AUTOSAR XML (schema 4-3-1)
standard types defined: Boolean, UInt8, SInt8, UInt16, SInt16, UInt32, SInt32, boolean, uint8, sint8, uint16, sint16, uint32, sint32
package /Components
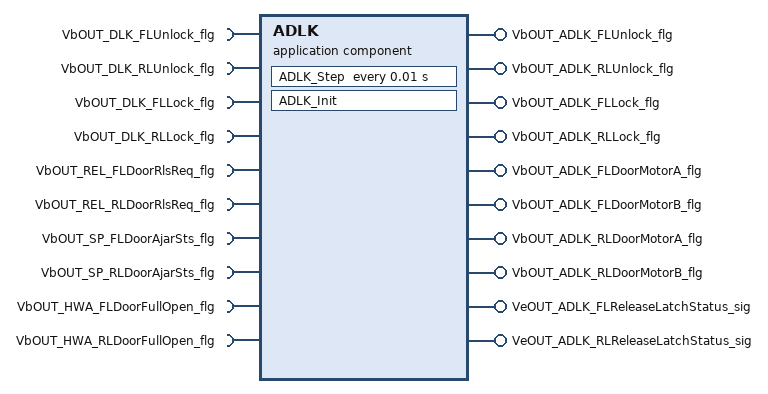
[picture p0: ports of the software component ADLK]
  application sw component type ADLK
    10 x require port:
      VbOUT_DLK_FLUnlock_flg: nonqueued-receiver-com-spec{data-element=VbOUT_DLK_FLUnlock_flg, init-value=FALSE}, required-interface=VbOUT_DLK_FLUnlock_flg
      VbOUT_DLK_RLUnlock_flg: nonqueued-receiver-com-spec{data-element=VbOUT_DLK_RLUnlock_flg, init-value=FALSE}, required-interface=VbOUT_DLK_RLUnlock_flg
      VbOUT_DLK_FLLock_flg: nonqueued-receiver-com-spec{data-element=VbOUT_DLK_FLLock_flg, init-value=FALSE}, required-interface=VbOUT_DLK_FLLock_flg
      VbOUT_DLK_RLLock_flg: nonqueued-receiver-com-spec{data-element=VbOUT_DLK_RLLock_flg, init-value=FALSE}, required-interface=VbOUT_DLK_RLLock_flg
      VbOUT_REL_FLDoorRlsReq_flg: nonqueued-receiver-com-spec{data-element=VbOUT_REL_FLDoorRlsReq_flg, init-value=FALSE}, required-interface=VbOUT_REL_FLDoorRlsReq_flg
      VbOUT_REL_RLDoorRlsReq_flg: nonqueued-receiver-com-spec{data-element=VbOUT_REL_RLDoorRlsReq_flg, init-value=FALSE}, required-interface=VbOUT_REL_RLDoorRlsReq_flg
      VbOUT_SP_FLDoorAjarSts_flg: nonqueued-receiver-com-spec{data-element=VbOUT_SP_FLDoorAjarSts_flg, init-value=FALSE}, required-interface=VbOUT_SP_FLDoorAjarSts_flg
      VbOUT_SP_RLDoorAjarSts_flg: nonqueued-receiver-com-spec{data-element=VbOUT_SP_RLDoorAjarSts_flg, init-value=FALSE}, required-interface=VbOUT_SP_RLDoorAjarSts_flg
      VbOUT_HWA_FLDoorFullOpen_flg: nonqueued-receiver-com-spec{data-element=VbOUT_HWA_FLDoorFullOpen_flg, init-value=FALSE}, required-interface=VbOUT_HWA_FLDoorFullOpen_flg
      VbOUT_HWA_RLDoorFullOpen_flg: nonqueued-receiver-com-spec{data-element=VbOUT_HWA_RLDoorFullOpen_flg, init-value=FALSE}, required-interface=VbOUT_HWA_RLDoorFullOpen_flg
    10 x provide port:
      VbOUT_ADLK_FLUnlock_flg: nonqueued-sender-com-spec{data-element=VbOUT_ADLK_FLUnlock_flg, init-value=FALSE}, provided-interface=VbOUT_ADLK_FLUnlock_flg
      VbOUT_ADLK_RLUnlock_flg: nonqueued-sender-com-spec{data-element=VbOUT_ADLK_RLUnlock_flg, init-value=FALSE}, provided-interface=VbOUT_ADLK_RLUnlock_flg
      VbOUT_ADLK_FLLock_flg: nonqueued-sender-com-spec{data-element=VbOUT_ADLK_FLLock_flg, init-value=FALSE}, provided-interface=VbOUT_ADLK_FLLock_flg
      VbOUT_ADLK_RLLock_flg: nonqueued-sender-com-spec{data-element=VbOUT_ADLK_RLLock_flg, init-value=FALSE}, provided-interface=VbOUT_ADLK_RLLock_flg
      VbOUT_ADLK_FLDoorMotorA_flg: nonqueued-sender-com-spec{data-element=VbOUT_ADLK_FLDoorMotorA_flg, init-value=FALSE}, provided-interface=VbOUT_ADLK_FLDoorMotorA_flg
      VbOUT_ADLK_FLDoorMotorB_flg: nonqueued-sender-com-spec{data-element=VbOUT_ADLK_FLDoorMotorB_flg, init-value=FALSE}, provided-interface=VbOUT_ADLK_FLDoorMotorB_flg
      VbOUT_ADLK_RLDoorMotorA_flg: nonqueued-sender-com-spec{data-element=VbOUT_ADLK_RLDoorMotorA_flg, init-value=FALSE}, provided-interface=VbOUT_ADLK_RLDoorMotorA_flg
      VbOUT_ADLK_RLDoorMotorB_flg: nonqueued-sender-com-spec{data-element=VbOUT_ADLK_RLDoorMotorB_flg, init-value=FALSE}, provided-interface=VbOUT_ADLK_RLDoorMotorB_flg
      VeOUT_ADLK_FLReleaseLatchStatus_sig: nonqueued-sender-com-spec{data-element=VeOUT_ADLK_FLReleaseLatchStatus_sig, init-value=0}, provided-interface=VeOUT_ADLK_FLReleaseLatchStatus_sig
      VeOUT_ADLK_RLReleaseLatchStatus_sig: nonqueued-sender-com-spec{data-element=VeOUT_ADLK_RLReleaseLatchStatus_sig, init-value=0}, provided-interface=VeOUT_ADLK_RLReleaseLatchStatus_sig
    behavior ADLK: data-type-mapping=DataTypeMappingsSet, handle-termination-and-restart=NO-SUPPORT
      init event ADLK_InitEvent: start-on-event=ADLK_Init
      timing event Event_Runnable_Step: start-on-event=ADLK_Step, period=0.01
      runnable ADLK_Init
        data-send-points:
          6 x access:
            OUT_VbOUT_ADLK_FLUnlock_flg_VbOUT_ADLK_FLUnlock_flg: accessed-variable=VbOUT_ADLK_FLUnlock_flg.VbOUT_ADLK_FLUnlock_flg
            OUT_VbOUT_ADLK_RLUnlock_flg_VbOUT_ADLK_RLUnlock_flg: accessed-variable=VbOUT_ADLK_RLUnlock_flg.VbOUT_ADLK_RLUnlock_flg
            OUT_VbOUT_ADLK_FLLock_flg_VbOUT_ADLK_FLLock_flg: accessed-variable=VbOUT_ADLK_FLLock_flg.VbOUT_ADLK_FLLock_flg
            OUT_VbOUT_ADLK_RLLock_flg_VbOUT_ADLK_RLLock_flg: accessed-variable=VbOUT_ADLK_RLLock_flg.VbOUT_ADLK_RLLock_flg
            OUT_VeOUT_ADLK_FLReleaseLatchStatus_sig_VeOUT_ADLK_FLReleaseLatchStatus_sig: accessed-variable=VeOUT_ADLK_FLReleaseLatchStatus_sig.VeOUT_ADLK_FLReleaseLatchStatus_sig
            OUT_VeOUT_ADLK_RLReleaseLatchStatus_sig_VeOUT_ADLK_RLReleaseLatchStatus_sig: accessed-variable=VeOUT_ADLK_RLReleaseLatchStatus_sig.VeOUT_ADLK_RLReleaseLatchStatus_sig
      runnable ADLK_Step
        data-receive-point-by-arguments:
          10 x access:
            IN_VbOUT_DLK_FLLock_flg_VbOUT_DLK_FLLock_flg: accessed-variable=VbOUT_DLK_FLLock_flg.VbOUT_DLK_FLLock_flg
            IN_VbOUT_DLK_FLUnlock_flg_VbOUT_DLK_FLUnlock_flg: accessed-variable=VbOUT_DLK_FLUnlock_flg.VbOUT_DLK_FLUnlock_flg
            IN_VbOUT_DLK_RLLock_flg_VbOUT_DLK_RLLock_flg: accessed-variable=VbOUT_DLK_RLLock_flg.VbOUT_DLK_RLLock_flg
            IN_VbOUT_DLK_RLUnlock_flg_VbOUT_DLK_RLUnlock_flg: accessed-variable=VbOUT_DLK_RLUnlock_flg.VbOUT_DLK_RLUnlock_flg
            IN_VbOUT_HWA_FLDoorFullOpen_flg_VbOUT_HWA_FLDoorFullOpen_flg: accessed-variable=VbOUT_HWA_FLDoorFullOpen_flg.VbOUT_HWA_FLDoorFullOpen_flg
            IN_VbOUT_HWA_RLDoorFullOpen_flg_VbOUT_HWA_RLDoorFullOpen_flg: accessed-variable=VbOUT_HWA_RLDoorFullOpen_flg.VbOUT_HWA_RLDoorFullOpen_flg
            IN_VbOUT_REL_FLDoorRlsReq_flg_VbOUT_REL_FLDoorRlsReq_flg: accessed-variable=VbOUT_REL_FLDoorRlsReq_flg.VbOUT_REL_FLDoorRlsReq_flg
            IN_VbOUT_REL_RLDoorRlsReq_flg_VbOUT_REL_RLDoorRlsReq_flg: accessed-variable=VbOUT_REL_RLDoorRlsReq_flg.VbOUT_REL_RLDoorRlsReq_flg
            IN_VbOUT_SP_FLDoorAjarSts_flg_VbOUT_SP_FLDoorAjarSts_flg: accessed-variable=VbOUT_SP_FLDoorAjarSts_flg.VbOUT_SP_FLDoorAjarSts_flg
            IN_VbOUT_SP_RLDoorAjarSts_flg_VbOUT_SP_RLDoorAjarSts_flg: accessed-variable=VbOUT_SP_RLDoorAjarSts_flg.VbOUT_SP_RLDoorAjarSts_flg
        data-send-points:
          10 x access:
            OUT_VbOUT_ADLK_FLUnlock_flg_VbOUT_ADLK_FLUnlock_flg: accessed-variable=VbOUT_ADLK_FLUnlock_flg.VbOUT_ADLK_FLUnlock_flg
            OUT_VbOUT_ADLK_RLUnlock_flg_VbOUT_ADLK_RLUnlock_flg: accessed-variable=VbOUT_ADLK_RLUnlock_flg.VbOUT_ADLK_RLUnlock_flg
            OUT_VbOUT_ADLK_FLLock_flg_VbOUT_ADLK_FLLock_flg: accessed-variable=VbOUT_ADLK_FLLock_flg.VbOUT_ADLK_FLLock_flg
            OUT_VbOUT_ADLK_RLLock_flg_VbOUT_ADLK_RLLock_flg: accessed-variable=VbOUT_ADLK_RLLock_flg.VbOUT_ADLK_RLLock_flg
            OUT_VbOUT_ADLK_FLDoorMotorA_flg_VbOUT_ADLK_FLDoorMotorA_flg: accessed-variable=VbOUT_ADLK_FLDoorMotorA_flg.VbOUT_ADLK_FLDoorMotorA_flg
            OUT_VbOUT_ADLK_FLDoorMotorB_flg_VbOUT_ADLK_FLDoorMotorB_flg: accessed-variable=VbOUT_ADLK_FLDoorMotorB_flg.VbOUT_ADLK_FLDoorMotorB_flg
            OUT_VbOUT_ADLK_RLDoorMotorA_flg_VbOUT_ADLK_RLDoorMotorA_flg: accessed-variable=VbOUT_ADLK_RLDoorMotorA_flg.VbOUT_ADLK_RLDoorMotorA_flg
            OUT_VbOUT_ADLK_RLDoorMotorB_flg_VbOUT_ADLK_RLDoorMotorB_flg: accessed-variable=VbOUT_ADLK_RLDoorMotorB_flg.VbOUT_ADLK_RLDoorMotorB_flg
            OUT_VeOUT_ADLK_FLReleaseLatchStatus_sig_VeOUT_ADLK_FLReleaseLatchStatus_sig: accessed-variable=VeOUT_ADLK_FLReleaseLatchStatus_sig.VeOUT_ADLK_FLReleaseLatchStatus_sig
            OUT_VeOUT_ADLK_RLReleaseLatchStatus_sig_VeOUT_ADLK_RLReleaseLatchStatus_sig: accessed-variable=VeOUT_ADLK_RLReleaseLatchStatus_sig.VeOUT_ADLK_RLReleaseLatchStatus_sig
package /DataTypes/ApplicationDataTypes
  application record data type TURN_DIAG_STRUCT: category=STRUCTURE, sw-calibration-access=READ-WRITE
    5 x application record element:
      OpenLoad: category=BOOLEAN, type=Boolean
      Overload: category=BOOLEAN, type=Boolean
      NormA2D: category=VALUE, type=UInt8
      Turn_LTH: category=VALUE, type=UInt8
      TurnCalib_th: category=VALUE, type=UInt8
  application array data type rt_Array_UInt8_8: category=ARRAY, sw-calibration-access=READ-WRITE
    element rt_Array_UInt8_8: category=VALUE, type=UInt8, array-size-semantics=FIXED-SIZE, max-number-of-elements=8
  7 x app type, all with sw-calibration-access=READ-WRITE:
    Boolean: category=BOOLEAN, compu {0=FALSE, 1=TRUE}
    UInt8: category=VALUE, compu {identical}, range phys 0..255
    SInt8: category=VALUE, compu {identical}, range phys -128..127
    UInt16: category=VALUE, compu {identical}, range phys 0..65535
    SInt16: category=VALUE, compu {identical}, range phys -32768..32767
    UInt32: category=VALUE, compu {identical}, range phys 0..4294967295
    SInt32: category=VALUE, compu {identical}, range phys -2147483648..2147483647
package /DataTypes/DataTypeMappings
  data type mapping set DataTypeMappingsSet
    data-type-maps:
      application-data-type=Boolean, implementation-data-type=Boolean
      application-data-type=UInt8, implementation-data-type=UInt8
      application-data-type=SInt8, implementation-data-type=SInt8
      application-data-type=UInt16, implementation-data-type=UInt16
      application-data-type=SInt16, implementation-data-type=SInt16
      application-data-type=UInt32, implementation-data-type=UInt32
      application-data-type=SInt32, implementation-data-type=SInt32
      application-data-type=TURN_DIAG_STRUCT, implementation-data-type=TURN_DIAG_STRUCT
      application-data-type=rt_Array_UInt8_8, implementation-data-type=rt_Array_UInt8_8
package /DataTypes/ImplementationDataTypes
  impl type TURN_DIAG_STRUCT: category=STRUCTURE
    5 x element, all with category=TYPE_REFERENCE:
      OpenLoad: implementation-data-type=Boolean
      Overload: implementation-data-type=Boolean
      NormA2D: implementation-data-type=UInt8
      Turn_LTH: implementation-data-type=UInt8
      TurnCalib_th: implementation-data-type=UInt8
  impl type rt_Array_UInt8_8: category=ARRAY
    element rt_Array_UInt8_8: array-size=8, array-size-semantics=FIXED-SIZE, implementation-data-type=UInt8
package /DataTypes/SwAddrMethods
  sw addr method CODE: section-type=CODE
  sw addr method CONST: section-type=CONST
  sw addr method VAR: section-type=VAR
package /DataTypes/Units
  unit NoUnit: factor-si-to-unit=1, offset-si-to-unit=0
package /Interfaces
  20 x sender receiver interface:
    VbOUT_DLK_FLUnlock_flg
      data VbOUT_DLK_FLUnlock_flg: category=BOOLEAN, sw-calibration-access=READ-ONLY, type=Boolean
    VbOUT_DLK_RLUnlock_flg
      data VbOUT_DLK_RLUnlock_flg: category=BOOLEAN, sw-calibration-access=READ-ONLY, type=Boolean
    VbOUT_DLK_FLLock_flg
      data VbOUT_DLK_FLLock_flg: category=BOOLEAN, sw-calibration-access=READ-ONLY, type=Boolean
    VbOUT_DLK_RLLock_flg
      data VbOUT_DLK_RLLock_flg: category=BOOLEAN, sw-calibration-access=READ-ONLY, type=Boolean
    VbOUT_REL_FLDoorRlsReq_flg
      data VbOUT_REL_FLDoorRlsReq_flg: category=BOOLEAN, sw-calibration-access=READ-ONLY, type=Boolean
    VbOUT_REL_RLDoorRlsReq_flg
      data VbOUT_REL_RLDoorRlsReq_flg: category=BOOLEAN, sw-calibration-access=READ-ONLY, type=Boolean
    VbOUT_SP_FLDoorAjarSts_flg
      data VbOUT_SP_FLDoorAjarSts_flg: category=BOOLEAN, sw-calibration-access=READ-ONLY, type=Boolean
    VbOUT_SP_RLDoorAjarSts_flg
      data VbOUT_SP_RLDoorAjarSts_flg: category=BOOLEAN, sw-calibration-access=READ-ONLY, type=Boolean
    VbOUT_HWA_FLDoorFullOpen_flg
      data VbOUT_HWA_FLDoorFullOpen_flg: category=BOOLEAN, sw-calibration-access=READ-ONLY, type=Boolean
    VbOUT_HWA_RLDoorFullOpen_flg
      data VbOUT_HWA_RLDoorFullOpen_flg: category=BOOLEAN, sw-calibration-access=READ-ONLY, type=Boolean
    VbOUT_ADLK_FLUnlock_flg
      data VbOUT_ADLK_FLUnlock_flg: category=BOOLEAN, sw-calibration-access=READ-ONLY, type=Boolean
    VbOUT_ADLK_RLUnlock_flg
      data VbOUT_ADLK_RLUnlock_flg: category=BOOLEAN, sw-calibration-access=READ-ONLY, type=Boolean
    VbOUT_ADLK_FLLock_flg
      data VbOUT_ADLK_FLLock_flg: category=BOOLEAN, sw-calibration-access=READ-ONLY, type=Boolean
    VbOUT_ADLK_RLLock_flg
      data VbOUT_ADLK_RLLock_flg: category=BOOLEAN, sw-calibration-access=READ-ONLY, type=Boolean
    VbOUT_ADLK_FLDoorMotorA_flg
      data VbOUT_ADLK_FLDoorMotorA_flg: category=BOOLEAN, sw-calibration-access=READ-ONLY, type=Boolean
    VbOUT_ADLK_FLDoorMotorB_flg
      data VbOUT_ADLK_FLDoorMotorB_flg: category=BOOLEAN, sw-calibration-access=READ-ONLY, type=Boolean
    VbOUT_ADLK_RLDoorMotorA_flg
      data VbOUT_ADLK_RLDoorMotorA_flg: category=BOOLEAN, sw-calibration-access=READ-ONLY, type=Boolean
    VbOUT_ADLK_RLDoorMotorB_flg
      data VbOUT_ADLK_RLDoorMotorB_flg: category=BOOLEAN, sw-calibration-access=READ-ONLY, type=Boolean
    VeOUT_ADLK_FLReleaseLatchStatus_sig
      data VeOUT_ADLK_FLReleaseLatchStatus_sig: category=VALUE, sw-calibration-access=READ-ONLY, type=UInt8
    VeOUT_ADLK_RLReleaseLatchStatus_sig
      data VeOUT_ADLK_RLReleaseLatchStatus_sig: category=VALUE, sw-calibration-access=READ-ONLY, type=UInt8
